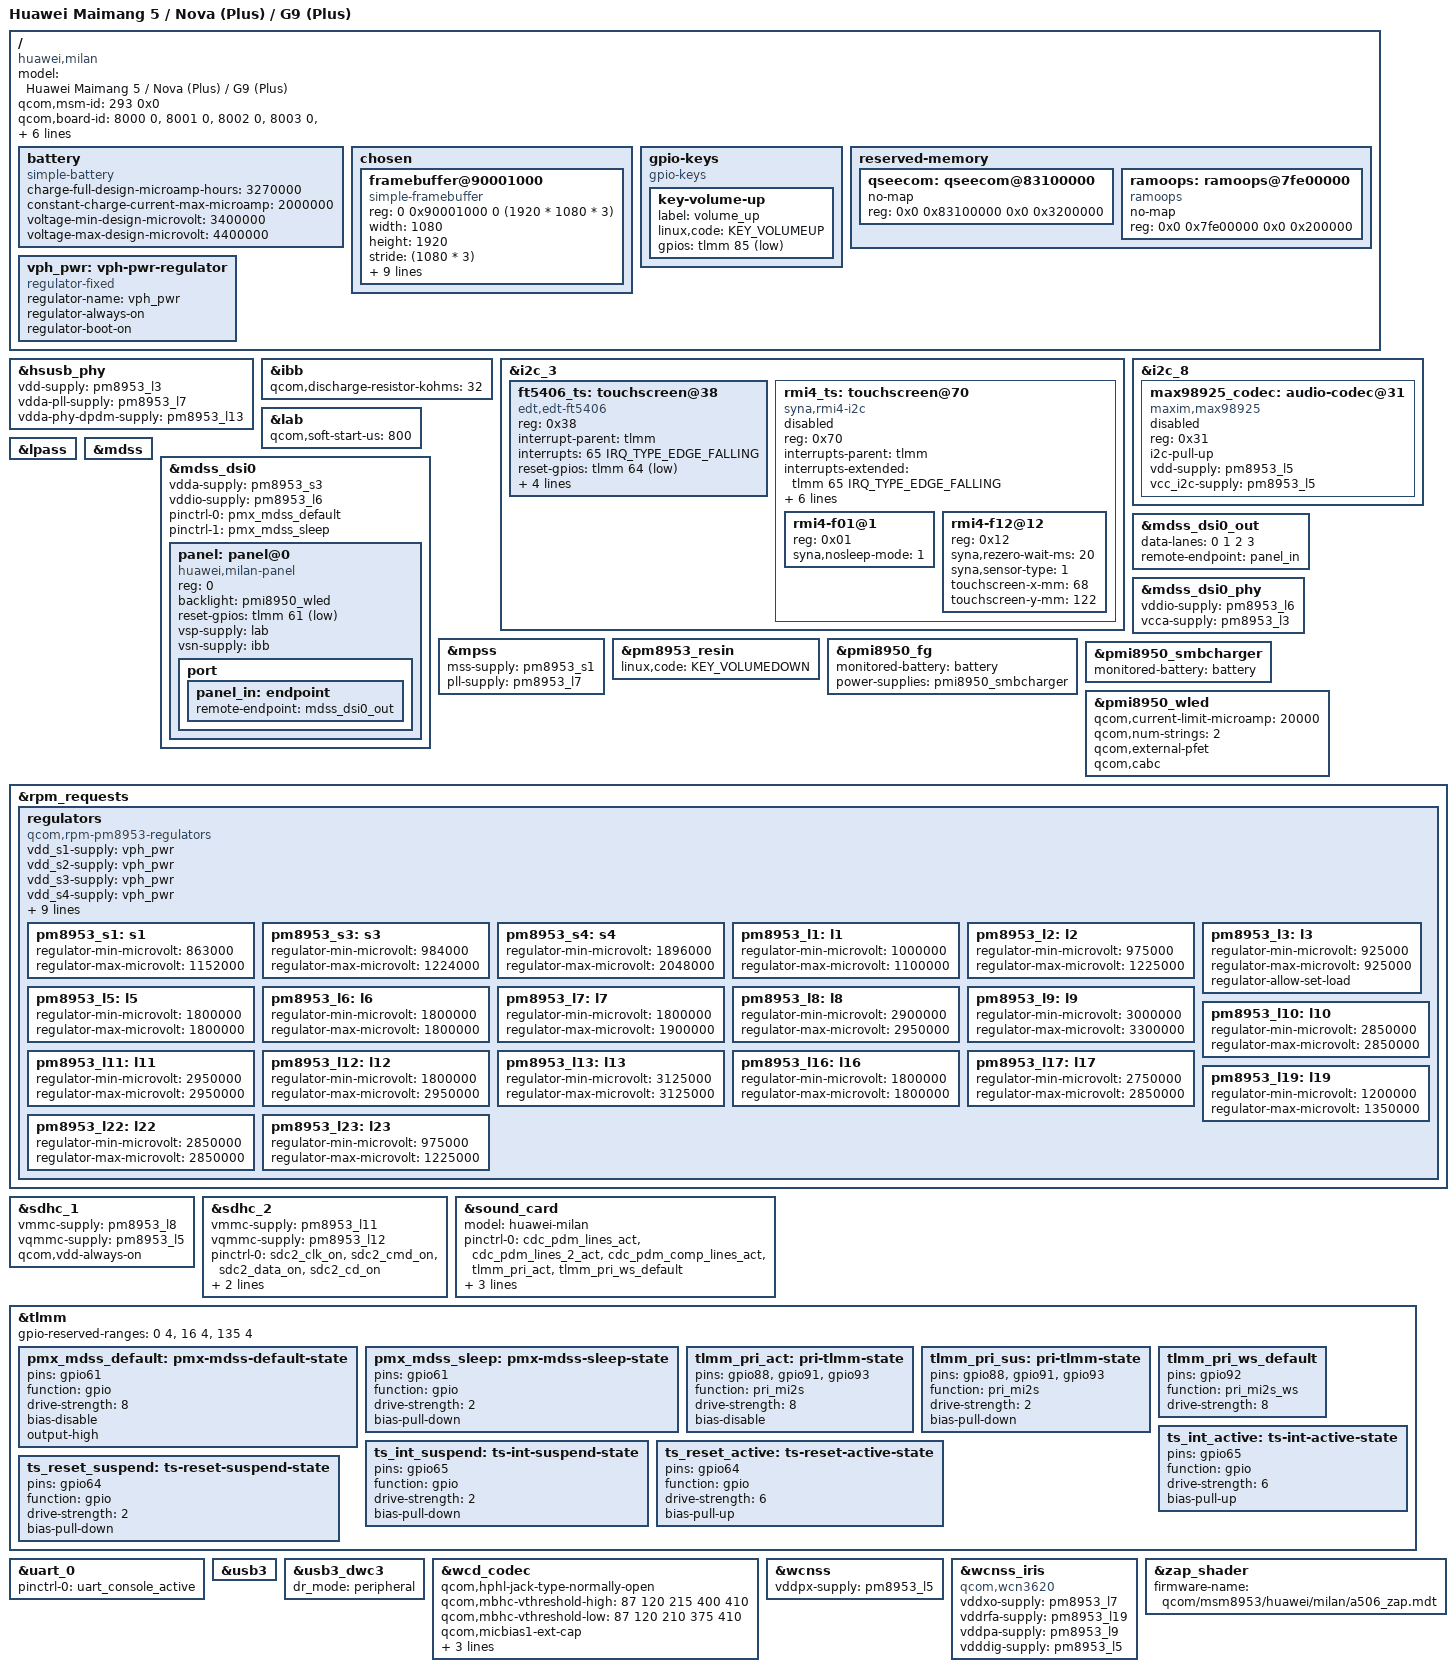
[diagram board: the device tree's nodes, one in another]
// SPDX-License-Identifier: BSD-3-Clause
/*
 * Copyright (c) 2024, Zhiyuan Bai <Bzy080408@outlook.com>
 * Copyright (c) 2024, Xinrui Li <2318678921@qq.com>
 */
/dts-v1/;

#include "msm8953.dtsi"
#include "pm8953.dtsi"
#include "pmi8950.dtsi"
#include <dt-bindings/gpio/gpio.h>
#include <dt-bindings/interrupt-controller/irq.h>
#include <dt-bindings/leds/common.h>


/ {
	model = "Huawei Maimang 5 / Nova (Plus) / G9 (Plus)";
	compatible = "huawei,milan", "qcom,msm8953";
	qcom,msm-id = <293 0x0>;
	qcom,board-id = <8000 0>, <8001 0>, <8002 0>, <8003 0>, <8016 0>,
			<8017 0>, <8018 0>, <8019 0>, <8032 0>, <8033 0>,
			<8035 0>, <8048 0>, <8049 0>, <8050 0>, <8051 0>,
			<8066 0>, <8064 0>, <8067 0>, <8080 0>, <8082 0>,
			<8083 0>, <8098 0>, <8099 0>, <8114 0>, <8130 0>;
	chassis-type = "handset";
	
	battery: battery {
		compatible = "simple-battery";
		charge-full-design-microamp-hours = <3270000>;
		constant-charge-current-max-microamp = <2000000>;
		voltage-min-design-microvolt = <3400000>;
		voltage-max-design-microvolt = <4400000>;
	};

	chosen {
		#address-cells = <2>;
		#size-cells = <2>;
		ranges;

		framebuffer@90001000 {
			compatible = "simple-framebuffer";
			reg = <0 0x90001000 0 (1920 * 1080 * 3)>;

			width = <1080>;
			height = <1920>;
			stride = <(1080 * 3)>;
			format = "r8g8b8";

			power-domains = <&gcc MDSS_GDSC>;
			
			clocks = <&gcc GCC_MDSS_AHB_CLK>,
				 <&gcc GCC_MDSS_AXI_CLK>,
				 <&gcc GCC_MDSS_VSYNC_CLK>,
				 <&gcc GCC_MDSS_MDP_CLK>,
				 <&gcc GCC_MDSS_BYTE0_CLK>,
				 <&gcc GCC_MDSS_PCLK0_CLK>,
				 <&gcc GCC_MDSS_ESC0_CLK>;
		};
	};

	gpio-keys {
		compatible = "gpio-keys";

		key-volume-up {
			label = "volume_up";
			linux,code = <KEY_VOLUMEUP>;
			gpios = <&tlmm 85 GPIO_ACTIVE_LOW>;
		};
	};

	reserved-memory {
		/delete-node/qseecom@85b00000;
		qseecom: qseecom@83100000 {
			no-map;
			reg = <0x0 0x83100000 0x0 0x3200000>;
		};

		ramoops: ramoops@7fe00000 {
		   compatible = "ramoops";
		   no-map;
		   reg = <0x0 0x7fe00000 0x0 0x200000>;
		};
	};

	vph_pwr: vph-pwr-regulator {
		compatible = "regulator-fixed";
		regulator-name = "vph_pwr";
		regulator-always-on;
		regulator-boot-on;
	};
};

&hsusb_phy {
	vdd-supply = <&pm8953_l3>;
	vdda-pll-supply = <&pm8953_l7>;
	vdda-phy-dpdm-supply = <&pm8953_l13>;

	status = "okay";
};

&ibb {
	qcom,discharge-resistor-kohms = <32>;
};

&i2c_3 {
	status = "okay";

	ft5406_ts: touchscreen@38 {
		compatible = "edt,edt-ft5406", "edt,edt-ft5x06";
		reg = <0x38>;

		interrupt-parent = <&tlmm>;
		interrupts = <65 IRQ_TYPE_EDGE_FALLING>;

		reset-gpios = <&tlmm 64 GPIO_ACTIVE_LOW>;

		vcc-supply = <&pm8953_l10>;
		iovcc-supply = <&pm8953_l6>;

		touchscreen-size-x = <1080>;
		touchscreen-size-y = <1920>;
		status = "okay";
	};

	rmi4_ts: touchscreen@70 {         // cannot use now
		reg = <0x70>;
		compatible = "syna,rmi4-i2c";
		interrupts-parent = <&tlmm>;
		interrupts-extended = <&tlmm 65 IRQ_TYPE_EDGE_FALLING>;

		#address-cells = <1>;
		#size-cells = <0>;

		vdd-supply = <&pm8953_l10>;
		vio-supply = <&pm8953_l6>;

		pinctrl-0 = <&ts_reset_active &ts_int_active>;
		pinctrl-1 = <&ts_reset_suspend &ts_int_suspend>;
		pinctrl-names = "default", "sleep";

		syna,reset-delay-ms = <200>;
		syna,startup-delay-ms = <500>;

		status = "disabled";

		rmi4-f01@1 {
			reg = <0x01>;
			syna,nosleep-mode = <1>;
		};

		rmi4-f12@12 {
			reg = <0x12>;
			syna,rezero-wait-ms = <20>;
			syna,sensor-type = <1>;
			touchscreen-x-mm = <68>;
			touchscreen-y-mm = <122>;
		};
	};

};

&i2c_8 {
	status = "okay";

	max98925_codec: audio-codec@31 {
		compatible = "maxim,max98925";
		reg = <0x31>;
		status = "disabled";

		i2c-pull-up;
		vdd-supply = <&pm8953_l5>;
		vcc_i2c-supply = <&pm8953_l5>;

		#sound-dai-cells = <0>;
	};
};

&lab {
	qcom,soft-start-us = <800>;
};

&lpass {
	status = "okay";
};

&mdss {
	status = "okay";
};

&mdss_dsi0 {
	vdda-supply = <&pm8953_s3>;
	vddio-supply = <&pm8953_l6>;

	pinctrl-0 = <&pmx_mdss_default>;
	pinctrl-1 = <&pmx_mdss_sleep>;
	pinctrl-names = "default", "sleep";

	status = "okay";

	panel: panel@0 {
		compatible = "huawei,milan-panel";
		reg = <0>;

		backlight = <&pmi8950_wled>;

		reset-gpios = <&tlmm 61 GPIO_ACTIVE_LOW>;

		vsp-supply = <&lab>;
		vsn-supply = <&ibb>;

		port {
			panel_in: endpoint {
				remote-endpoint = <&mdss_dsi0_out>;
			};
		};
	};
};

&mdss_dsi0_out {
	data-lanes = <0 1 2 3>;
	remote-endpoint = <&panel_in>;
};

&mdss_dsi0_phy {
	vddio-supply = <&pm8953_l6>;
	vcca-supply = <&pm8953_l3>;

	status = "okay";
};

&mpss {
	mss-supply = <&pm8953_s1>;
	pll-supply = <&pm8953_l7>;

	status = "okay";
};

&pm8953_resin {
	linux,code = <KEY_VOLUMEDOWN>;

	status = "okay";
};

&pmi8950_fg {
	monitored-battery = <&battery>;
	power-supplies = <&pmi8950_smbcharger>;

	status = "okay";
};

&pmi8950_smbcharger {
	monitored-battery = <&battery>;

	status = "okay";
};

&pmi8950_wled {
	qcom,current-limit-microamp = <20000>;
	qcom,num-strings = <2>;
	qcom,external-pfet;
	qcom,cabc;

	status = "okay";
};

&rpm_requests {
	regulators {
		compatible = "qcom,rpm-pm8953-regulators";
		vdd_s1-supply = <&vph_pwr>;
		vdd_s2-supply = <&vph_pwr>;
		vdd_s3-supply = <&vph_pwr>;
		vdd_s4-supply = <&vph_pwr>;
		vdd_s5-supply = <&vph_pwr>;
		vdd_s6-supply = <&vph_pwr>;
		vdd_s7-supply = <&vph_pwr>;
		vdd_l1-supply = <&pm8953_s3>;
		vdd_l2_l3-supply = <&pm8953_s3>;
		vdd_l4_l5_l6_l7_l16_l19-supply = <&pm8953_s4>;
		vdd_l8_l11_l12_l13_l14_l15-supply = <&vph_pwr>;
		vdd_l9_l10_l17_l18_l22-supply = <&vph_pwr>;
		vdd_l23-supply = <&pm8953_s3>;

		pm8953_s1: s1 {
			regulator-min-microvolt = <863000>;
			regulator-max-microvolt = <1152000>;
		};

		pm8953_s3: s3 {
			regulator-min-microvolt = <984000>;
			regulator-max-microvolt = <1224000>;
		};

		pm8953_s4: s4 {
			regulator-min-microvolt = <1896000>;
			regulator-max-microvolt = <2048000>;
		};

		pm8953_l1: l1 {
			regulator-min-microvolt = <1000000>;
			regulator-max-microvolt = <1100000>;
		};

		pm8953_l2: l2 {
			regulator-min-microvolt = <975000>;
			regulator-max-microvolt = <1225000>;
		};

		pm8953_l3: l3 {
			regulator-min-microvolt = <925000>;
			regulator-max-microvolt = <925000>;
			regulator-allow-set-load;
		};

		pm8953_l5: l5 {
			regulator-min-microvolt = <1800000>;
			regulator-max-microvolt = <1800000>;
		};

		pm8953_l6: l6 {
			regulator-min-microvolt = <1800000>;
			regulator-max-microvolt = <1800000>;
		};

		pm8953_l7: l7 {
			regulator-min-microvolt = <1800000>;
			regulator-max-microvolt = <1900000>;
		};

		pm8953_l8: l8 {
			regulator-min-microvolt = <2900000>;
			regulator-max-microvolt = <2950000>;
		};

		pm8953_l9: l9 {
			regulator-min-microvolt = <3000000>;
			regulator-max-microvolt = <3300000>;
		};

		pm8953_l10: l10 {
			regulator-min-microvolt = <2850000>;
			regulator-max-microvolt = <2850000>;
		};

		pm8953_l11: l11 {
			regulator-min-microvolt = <2950000>;
			regulator-max-microvolt = <2950000>;
		};

		pm8953_l12: l12 {
			regulator-min-microvolt = <1800000>;
			regulator-max-microvolt = <2950000>;
		};

		pm8953_l13: l13 {
			regulator-min-microvolt = <3125000>;
			regulator-max-microvolt = <3125000>;
		};

		pm8953_l16: l16 {
			regulator-min-microvolt = <1800000>;
			regulator-max-microvolt = <1800000>;
		};

		pm8953_l17: l17 {
			regulator-min-microvolt = <2750000>;
			regulator-max-microvolt = <2850000>;
		};

		pm8953_l19: l19 {
			regulator-min-microvolt = <1200000>;
			regulator-max-microvolt = <1350000>;
		};

		pm8953_l22: l22 {
			regulator-min-microvolt = <2850000>;
			regulator-max-microvolt = <2850000>;
		};

		pm8953_l23: l23 {
			regulator-min-microvolt = <975000>;
			regulator-max-microvolt = <1225000>;
		};
	};
};

&sdhc_1 {
	vmmc-supply = <&pm8953_l8>;
	vqmmc-supply = <&pm8953_l5>;
	qcom,vdd-always-on;

	status = "okay";
};

&sdhc_2 {
	vmmc-supply = <&pm8953_l11>;
	vqmmc-supply = <&pm8953_l12>;

	pinctrl-0 = <&sdc2_clk_on &sdc2_cmd_on &sdc2_data_on &sdc2_cd_on>;
	pinctrl-1 = <&sdc2_clk_off &sdc2_cmd_off &sdc2_data_off &sdc2_cd_off>;
	pinctrl-names = "default", "sleep";

	status = "okay";
};

&sound_card {
	model = "huawei-milan";

	pinctrl-0 = <&cdc_pdm_lines_act
			&cdc_pdm_lines_2_act
			&cdc_pdm_comp_lines_act
			&tlmm_pri_act
			&tlmm_pri_ws_default>;
	pinctrl-1 = <&cdc_pdm_lines_sus
			&cdc_pdm_lines_2_sus
			&cdc_pdm_comp_lines_sus
			&tlmm_pri_sus
			&tlmm_pri_ws_default>;
	pinctrl-names = "default", "sleep";

	status = "okay";
};



&tlmm {
	gpio-reserved-ranges = <0 4>, <16 4>, <135 4>;

	pmx_mdss_default: pmx-mdss-default-state {
		pins = "gpio61";
		function = "gpio";
		drive-strength = <8>;
		bias-disable;
		output-high;
	};

	pmx_mdss_sleep: pmx-mdss-sleep-state {
		pins = "gpio61";
		function = "gpio";
		drive-strength = <2>;
		bias-pull-down;
	};

	tlmm_pri_act: pri-tlmm-state {
		pins = "gpio88", "gpio91", "gpio93";
		function = "pri_mi2s";
		drive-strength = <8>;
		bias-disable;
	};

	tlmm_pri_sus: pri-tlmm-state {
		pins = "gpio88", "gpio91", "gpio93";
		function = "pri_mi2s";
		drive-strength = <2>;
		bias-pull-down;
	};

	tlmm_pri_ws_default: tlmm_pri_ws_default {
		pins = "gpio92";
		function = "pri_mi2s_ws";
		drive-strength = <8>;
	};

	ts_int_active: ts-int-active-state {
		pins = "gpio65";
		function = "gpio";
		drive-strength = <6>;
		bias-pull-up;
	};

	ts_int_suspend: ts-int-suspend-state {
		pins = "gpio65";
		function = "gpio";
		drive-strength = <2>;
		bias-pull-down;
	};

	ts_reset_active: ts-reset-active-state {
		pins = "gpio64";
		function = "gpio";
		drive-strength = <6>;
		bias-pull-up;
	};

	ts_reset_suspend: ts-reset-suspend-state {
		pins = "gpio64";
		function = "gpio";
		drive-strength = <2>;
		bias-pull-down;
	};
};

&uart_0 {
	pinctrl-0 = <&uart_console_active>;
	pinctrl-names = "default";

	status = "okay";
};

&usb3 {
	status = "okay";
};

&usb3_dwc3 {
	dr_mode = "peripheral";
};

&wcd_codec {
	qcom,hphl-jack-type-normally-open;
	qcom,mbhc-vthreshold-high = <87 120 215 400 410>;
	qcom,mbhc-vthreshold-low = <87 120 210 375 410>;
	qcom,micbias1-ext-cap;

	vdd-cdc-io-supply = <&pm8953_l5>;
	vdd-cdc-tx-rx-cx-supply = <&pm8953_s4>;
	vdd-micbias-supply = <&pm8953_l13>;

	status = "okay";
};

&wcnss {
	vddpx-supply = <&pm8953_l5>;

	status = "okay";
};

// Only 2.4G wifi,use wcn3620 replace

&wcnss_iris {
	compatible = "qcom,wcn3620";

	vddxo-supply = <&pm8953_l7>;
	vddrfa-supply = <&pm8953_l19>;
	vddpa-supply = <&pm8953_l9>;
	vdddig-supply = <&pm8953_l5>;
};

&zap_shader {
	firmware-name = "qcom/msm8953/huawei/milan/a506_zap.mdt";
};
